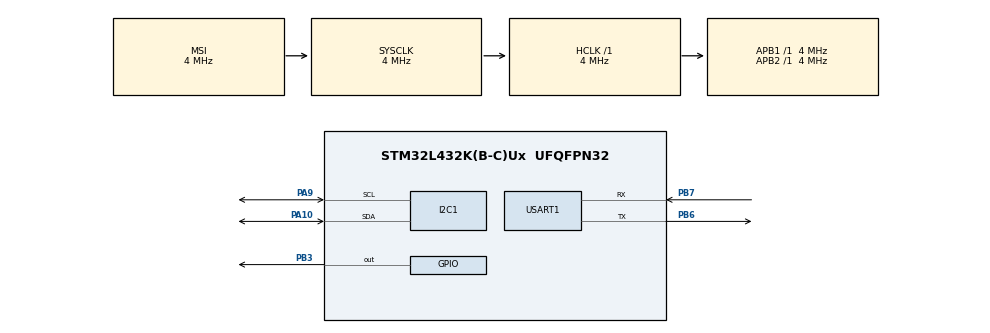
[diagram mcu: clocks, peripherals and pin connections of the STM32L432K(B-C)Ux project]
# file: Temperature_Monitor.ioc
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Mcu.Family=STM32L4
Mcu.Name=STM32L432K(B-C)Ux
Mcu.Package=UFQFPN32
NVIC.I2C1_EV_IRQn=true\:0\:0\:false\:false\:true\:true\:true
NVIC.PriorityGroup=NVIC_PRIORITYGROUP_4
NVIC.RCC_IRQn=true\:0\:0\:false\:false\:true\:true\:false
NVIC.USART1_IRQn=true\:0\:0\:false\:false\:true\:true\:true
PA10.Mode=I2C
PA10.Signal=I2C1_SDA
PA13\ (JTMS-SWDIO).Mode=Serial_Wire
PA13\ (JTMS-SWDIO).Signal=SYS_JTMS-SWDIO
PA14\ (JTCK-SWCLK).Mode=Serial_Wire
PA14\ (JTCK-SWCLK).Signal=SYS_JTCK-SWCLK
PA9.Mode=I2C
PA9.Signal=I2C1_SCL
PB3\ (JTDO-TRACESWO).Signal=GPIO_Output
PB6.Mode=Asynchronous
PB6.Signal=USART1_TX
PB7.Mode=Asynchronous
PB7.Signal=USART1_RX
PC14-OSC32_IN\ (PC14).Mode=LSE-External-Oscillator
PC14-OSC32_IN\ (PC14).Signal=RCC_OSC32_IN
PC15-OSC32_OUT\ (PC15).Mode=LSE-External-Oscillator
PC15-OSC32_OUT\ (PC15).Signal=RCC_OSC32_OUT
ProjectManager.HeapSize=0x200
ProjectManager.StackSize=0x400
ProjectManager.TargetToolchain=MDK-ARM V5
RCC.AHBFreq_Value=4000000
RCC.APB1Freq_Value=4000000
RCC.APB1TimFreq_Value=4000000
RCC.APB2Freq_Value=4000000
RCC.APB2TimFreq_Value=4000000
RCC.CortexFreq_Value=4000000
RCC.HCLKFreq_Value=4000000
RCC.HSE_VALUE=8000000
RCC.HSI48_VALUE=48000000
RCC.HSI_VALUE=16000000
RCC.MSI_VALUE=4000000
RCC.PLLN=16
RCC.SYSCLKFreq_VALUE=4000000
RCC.VCOOutputFreq_Value=64000000
USART1.VirtualMode-Asynchronous=VM_ASYNC
board=custom

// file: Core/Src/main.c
/* USER CODE BEGIN Header */
/**
  ******************************************************************************
  * @file           : main.c
  * @brief          : Main program body
  ******************************************************************************
  * @attention
  *
  * <h2><center>&copy; Copyright (c) 2021 STMicroelectronics.
  * All rights reserved.</center></h2>
  *
  * This software component is licensed by ST under BSD 3-Clause license,
  * the "License"; You may not use this file except in compliance with the
  * License. You may obtain a copy of the License at:
  *                        opensource.org/licenses/BSD-3-Clause
  *
  ******************************************************************************
  */
/* USER CODE END Header */
#include "main.h"
#include "queue.h"
#include "tasks.h"

I2C_HandleTypeDef hi2c1;

UART_HandleTypeDef huart1;

uint8_t reading_buffer[] = {0,0,'.',0,0};
uint8_t welcome_text[] = "\r\n------------------Temeperature Monitor------------------\r\nYou are allowed to enter the threshold for the allowed \r\ntemperature in the following format xx.xx\r\nPlease, enter the temperature: ";
uint8_t temp_entering_text[] = "\r\nPlease, enter the temperature: ";

/* USER CODE BEGIN PV */
int volatile index_reading_buffer = 0;
int volatile threshold_temp_whole=30;
int volatile threshold_temp_decimal=0;
int volatile actual_temp_whole;
int volatile actual_temp_decimal;
int volatile threshold_exceeded_flag=0;
/* USER CODE END PV */

void SystemClock_Config(void);
static void MX_GPIO_Init(void);
static void MX_I2C1_Init(void);
static void MX_USART1_UART_Init(void);

int main(void)
{

  /* MCU Configuration--------------------------------------------------------*/

  /* Reset of all peripherals, Initializes the Flash interface and the Systick. */
  HAL_Init();

  /* Configure the system clock */
  SystemClock_Config();

  /* Initialize all configured peripherals */
  MX_GPIO_Init();
  MX_I2C1_Init();
  MX_USART1_UART_Init();
	__HAL_UART_ENABLE_IT(&huart1, UART_IT_RXNE);
  /* USER CODE BEGIN 2 */
	//SysTick->LOAD= 32000000-1;
	//SysTick->CTRL =7;
	init();
	HAL_UART_Transmit(&huart1,welcome_text, sizeof(welcome_text), HAL_MAX_DELAY);
	QueTask(task_1_read_temperature, 2);

  /* USER CODE END 2 */

  /* Infinite loop */
  while (1)
  {
		Dispatch();
  }
}

void SystemClock_Config(void)
{
  RCC_OscInitTypeDef RCC_OscInitStruct = {0};
  RCC_ClkInitTypeDef RCC_ClkInitStruct = {0};
  RCC_PeriphCLKInitTypeDef PeriphClkInit = {0};

  /** Configure LSE Drive Capability
  */
  HAL_PWR_EnableBkUpAccess();
  __HAL_RCC_LSEDRIVE_CONFIG(RCC_LSEDRIVE_LOW);
  /** Initializes the RCC Oscillators according to the specified parameters
  * in the RCC_OscInitTypeDef structure.
  */
  RCC_OscInitStruct.OscillatorType = RCC_OSCILLATORTYPE_LSE|RCC_OSCILLATORTYPE_MSI;
  RCC_OscInitStruct.LSEState = RCC_LSE_ON;
  RCC_OscInitStruct.MSIState = RCC_MSI_ON;
  RCC_OscInitStruct.MSICalibrationValue = 0;
  RCC_OscInitStruct.MSIClockRange = RCC_MSIRANGE_6;
  RCC_OscInitStruct.PLL.PLLState = RCC_PLL_NONE;
  if (HAL_RCC_OscConfig(&RCC_OscInitStruct) != HAL_OK)
  {
    Error_Handler();
  }
  /** Initializes the CPU, AHB and APB buses clocks
  */
  RCC_ClkInitStruct.ClockType = RCC_CLOCKTYPE_HCLK|RCC_CLOCKTYPE_SYSCLK
                              |RCC_CLOCKTYPE_PCLK1|RCC_CLOCKTYPE_PCLK2;
  RCC_ClkInitStruct.SYSCLKSource = RCC_SYSCLKSOURCE_MSI;
  RCC_ClkInitStruct.AHBCLKDivider = RCC_SYSCLK_DIV1;
  RCC_ClkInitStruct.APB1CLKDivider = RCC_HCLK_DIV1;
  RCC_ClkInitStruct.APB2CLKDivider = RCC_HCLK_DIV1;

  if (HAL_RCC_ClockConfig(&RCC_ClkInitStruct, FLASH_LATENCY_0) != HAL_OK)
  {
    Error_Handler();
  }
  PeriphClkInit.PeriphClockSelection = RCC_PERIPHCLK_USART1|RCC_PERIPHCLK_I2C1;
  PeriphClkInit.Usart1ClockSelection = RCC_USART1CLKSOURCE_PCLK2;
  PeriphClkInit.I2c1ClockSelection = RCC_I2C1CLKSOURCE_PCLK1;
  if (HAL_RCCEx_PeriphCLKConfig(&PeriphClkInit) != HAL_OK)
  {
    Error_Handler();
  }
  /** Configure the main internal regulator output voltage
  */
  if (HAL_PWREx_ControlVoltageScaling(PWR_REGULATOR_VOLTAGE_SCALE1) != HAL_OK)
  {
    Error_Handler();
  }
  /** Enable MSI Auto calibration
  */
  HAL_RCCEx_EnableMSIPLLMode();
}

static void MX_I2C1_Init(void)
{

  hi2c1.Instance = I2C1;
  hi2c1.Init.Timing = 0x00000E14;
  hi2c1.Init.OwnAddress1 = 0;
  hi2c1.Init.AddressingMode = I2C_ADDRESSINGMODE_7BIT;
  hi2c1.Init.DualAddressMode = I2C_DUALADDRESS_DISABLE;
  hi2c1.Init.OwnAddress2 = 0;
  hi2c1.Init.OwnAddress2Masks = I2C_OA2_NOMASK;
  hi2c1.Init.GeneralCallMode = I2C_GENERALCALL_DISABLE;
  hi2c1.Init.NoStretchMode = I2C_NOSTRETCH_DISABLE;
  if (HAL_I2C_Init(&hi2c1) != HAL_OK)
  {
    Error_Handler();
  }
  /** Configure Analogue filter
  */
  if (HAL_I2CEx_ConfigAnalogFilter(&hi2c1, I2C_ANALOGFILTER_ENABLE) != HAL_OK)
  {
    Error_Handler();
  }
  /** Configure Digital filter
  */
  if (HAL_I2CEx_ConfigDigitalFilter(&hi2c1, 0) != HAL_OK)
  {
    Error_Handler();
  }

}

static void MX_USART1_UART_Init(void)
{

  huart1.Instance = USART1;
  huart1.Init.BaudRate = 115200;
  huart1.Init.WordLength = UART_WORDLENGTH_8B;
  huart1.Init.StopBits = UART_STOPBITS_1;
  huart1.Init.Parity = UART_PARITY_NONE;
  huart1.Init.Mode = UART_MODE_TX_RX;
  huart1.Init.HwFlowCtl = UART_HWCONTROL_NONE;
  huart1.Init.OverSampling = UART_OVERSAMPLING_16;
  huart1.Init.OneBitSampling = UART_ONE_BIT_SAMPLE_DISABLE;
  huart1.AdvancedInit.AdvFeatureInit = UART_ADVFEATURE_NO_INIT;
  if (HAL_UART_Init(&huart1) != HAL_OK)
  {
    Error_Handler();
  }

}

static void MX_GPIO_Init(void)
{
  GPIO_InitTypeDef GPIO_InitStruct = {0};

  /* GPIO Ports Clock Enable */
  __HAL_RCC_GPIOC_CLK_ENABLE();
  __HAL_RCC_GPIOA_CLK_ENABLE();
  __HAL_RCC_GPIOB_CLK_ENABLE();

  /*Configure GPIO pin Output Level */
  HAL_GPIO_WritePin(GPIOB, GPIO_PIN_3, GPIO_PIN_RESET);

  /*Configure GPIO pin : PB3 */
  GPIO_InitStruct.Pin = GPIO_PIN_3;
  GPIO_InitStruct.Mode = GPIO_MODE_OUTPUT_PP;
  GPIO_InitStruct.Pull = GPIO_NOPULL;
  GPIO_InitStruct.Speed = GPIO_SPEED_FREQ_LOW;
  HAL_GPIO_Init(GPIOB, &GPIO_InitStruct);

}

void Error_Handler(void)
{
  __disable_irq();
  while (1)
  {
  }
}

/************************ (C) COPYRIGHT STMicroelectronics *****END OF FILE****/
